# psoc6a2m register map
Vendor: Cypress Semiconductor; Series: psoc6a2m; File version: 1.0
CPU: CM4 r0p1, little endian, MPU, FPU, VTOR, 3 interrupt priority bits
Registers are 32-bit, read-write, reset 0x0 unless marked. A register's access mark holds for its fields unless they carry their own. Offsets are from the block's base; [hi:lo] are bit positions; lines under a group give offsets from that group.

## SDHC0 (part 3 of 4) — SD/eMMC Host Controller
Base 0x40460000
Same registers: SDHC1 0x40470000
0x1000 CORE group — MMIO for Synopsys Mobile Storage Host Controller IP
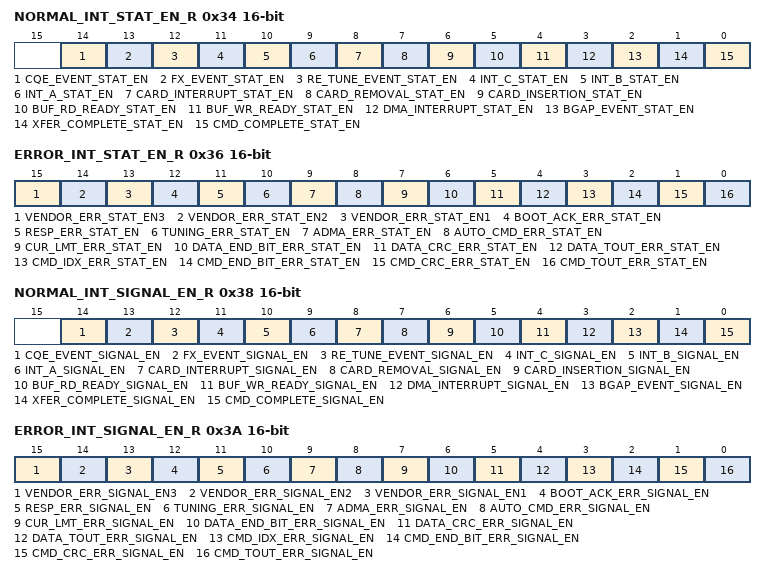
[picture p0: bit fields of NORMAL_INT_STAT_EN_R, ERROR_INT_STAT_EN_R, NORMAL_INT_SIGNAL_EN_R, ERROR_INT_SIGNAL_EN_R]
  0x34 NORMAL_INT_STAT_EN_R 16-bit — Normal Interrupt Status Enable Register
    [14] CQE_EVENT_STAT_EN — CQE Event Status Enable Values: - 0x0 (FALSE): Masked - 0x1 (TRUE): Enabled
    [13] FX_EVENT_STAT_EN — FX Event Status Enable This bit is added from Version 4.10. Values: - 0x0 (FALSE): Masked - 0x1 (TRUE): Enabled
    [12] RE_TUNE_EVENT_STAT_EN — Re-Tuning Event (UHS-I only) Status Enable Values: - 0x0 (FALSE): Masked - 0x1 (TRUE): Enabled
    [11] INT_C_STAT_EN — INT_C (Embedded) Status Enable If this bit is set to 0, the Host Controller clears the interrupt request to the System. The Host Driver may clear this bit before servicing the INT_C and may set this bit again after all interrupt requests to INT_C pin are cleared to prevent inadvertent interrupts. Values: - 0x0 (FALSE): Masked - 0x1 (TRUE): Enabled
    [10] INT_B_STAT_EN — INT_B (Embedded) Status Enable If this bit is set to 0, the Host Controller clears the interrupt request to the System. The Host Driver may clear this bit before servicing the INT_B and may set this bit again after all interrupt requests to INT_B pin are cleared to prevent inadvertent interrupts. Values: - 0x0 (FALSE): Masked - 0x1 (TRUE): Enabled
    [9] INT_A_STAT_EN — INT_A (Embedded) Status Enable If this bit is set to 0, the Host Controller clears the interrupt request to the System. The Host Driver may clear this bit before servicing the INT_A and may set this bit again after all interrupt requests to INT_A pin are cleared to prevent inadvertent interrupts. Values: - 0x0 (FALSE): Masked - 0x1 (TRUE): Enabled
    [8] CARD_INTERRUPT_STAT_EN — Card Interrupt Status Enable If this bit is set to 0, the Host Controller clears the interrupt request to the System. The Card Interrupt detection is stopped when this bit is cleared and restarted when this bit is set to 1. The Host Driver may clear the Card Interrupt Status Enable before servicing the Card Interrupt and may set this bit again after all interrupt requests from the card are cleared to prevent inadvertent interrupts. By setting this bit to 0, interrupt input must be masked by implementation so that the interrupt input is not affected by external signal in any state (for example, floating). Values: - 0x0 (FALSE): Masked - 0x1 (TRUE): Enabled
    [7] CARD_REMOVAL_STAT_EN — Card Removal Status Enable Values: - 0x0 (FALSE): Masked - 0x1 (TRUE): Enabled
    [6] CARD_INSERTION_STAT_EN — Card Insertion Status Enable Values: - 0x0 (FALSE): Masked - 0x1 (TRUE): Enabled
    [5] BUF_RD_READY_STAT_EN — Buffer Read Ready Status Enable Values: - 0x0 (FALSE): Masked - 0x1 (TRUE): Enabled
    [4] BUF_WR_READY_STAT_EN — Buffer Write Ready Status Enable Values: - 0x0 (FALSE): Masked - 0x1 (TRUE): Enabled
    [3] DMA_INTERRUPT_STAT_EN — DMA Interrupt Status Enable Values: - 0x0 (FALSE): Masked - 0x1 (TRUE): Enabled
    [2] BGAP_EVENT_STAT_EN — Block Gap Event Status Enable Values: - 0x0 (FALSE): Masked - 0x1 (TRUE): Enabled
    [1] XFER_COMPLETE_STAT_EN — Transfer Complete Status Enable Values: - 0x0 (FALSE): Masked - 0x1 (TRUE): Enabled
    [0] CMD_COMPLETE_STAT_EN — Command Complete Status Enable Values: - 0x0 (FALSE): Masked - 0x1 (TRUE): Enabled
  0x36 ERROR_INT_STAT_EN_R 16-bit — Error Interrupt Status Enable Register
    [15] VENDOR_ERR_STAT_EN3
    [14] VENDOR_ERR_STAT_EN2
    [13] VENDOR_ERR_STAT_EN1
    [12] BOOT_ACK_ERR_STAT_EN — Boot Acknowledgment Error (eMMC Mode only) Setting this bit to 1 enables setting of Boot Acknowledgment Error in Error Interrupt Status register (ERROR_INT_STAT_R). Values: - 0x0 (FALSE): Masked - 0x1 (TRUE): Enabled
    [11] RESP_ERR_STAT_EN — Response Error Status Enable (SD Mode only) Values: - 0x0 (FALSE): Masked - 0x1 (TRUE): Enabled
    [10] TUNING_ERR_STAT_EN — Tuning Error Status Enable (UHS-I Mode only) Values: - 0x0 (FALSE): Masked - 0x1 (TRUE): Enabled
    [9] ADMA_ERR_STAT_EN — ADMA Error Status Enable Values: - 0x0 (FALSE): Masked - 0x1 (TRUE): Enabled
    [8] AUTO_CMD_ERR_STAT_EN — Auto CMD Error Status Enable (SD/eMMC Mode only). Values: - 0x0 (FALSE): Masked - 0x1 (TRUE): Enabled
    [7] CUR_LMT_ERR_STAT_EN — Current Limit Error Status Enable Values: - 0x0 (FALSE): Masked - 0x1 (TRUE): Enabled
    [6] DATA_END_BIT_ERR_STAT_EN — Data End Bit Error Status Enable (SD/eMMC Mode only). Values: - 0x0 (FALSE): Masked - 0x1 (TRUE): Enabled
    [5] DATA_CRC_ERR_STAT_EN — Data CRC Error Status Enable (SD/eMMC Mode only) Values: - 0x0 (FALSE): Masked - 0x1 (TRUE): Enabled
    [4] DATA_TOUT_ERR_STAT_EN — Data Timeout Error Status Enable (SD/eMMC Mode only) Values: - 0x0 (FALSE): Masked - 0x1 (TRUE): Enabled
    [3] CMD_IDX_ERR_STAT_EN — Command Index Error Status Enable (SD/eMMC Mode only) Values: - 0x0 (FALSE): Masked - 0x1 (TRUE): Enabled
    [2] CMD_END_BIT_ERR_STAT_EN — Command End Bit Error Status Enable (SD/eMMC Mode only) Values: - 0x0 (FALSE): Masked - 0x1 (TRUE): Enabled
    [1] CMD_CRC_ERR_STAT_EN — ommand CRC Error Status Enable (SD/eMMC Mode only) Values: - 0x0 (FALSE): Masked - 0x1 (TRUE): Enabled
    [0] CMD_TOUT_ERR_STAT_EN — Command Timeout Error Status Enable (SD/eMMC Mode only). Values: - 0x0 (FALSE): Masked - 0x1 (TRUE): Enabled
  0x38 NORMAL_INT_SIGNAL_EN_R 16-bit — Normal Interrupt Signal Enable Register
    [14] CQE_EVENT_SIGNAL_EN — Command Queuing Engine Event Signal Enable Values: - 0x0 (FALSE): Masked - 0x1 (TRUE): Enabled
    [13] FX_EVENT_SIGNAL_EN — FX Event Signal Enable Values: - 0x0 (FALSE): Masked - 0x1 (TRUE): Enabled
    [12] RE_TUNE_EVENT_SIGNAL_EN — Re-Tuning Event (UHS-I only) Signal Enable. Values: - 0x0 (FALSE): Masked - 0x1 (TRUE): Enabled
    [11] INT_C_SIGNAL_EN — INT_C (Embedded) Signal Enable Values: - 0x0 (FALSE): Masked - 0x1 (TRUE): Enabled
    [10] INT_B_SIGNAL_EN — INT_B (Embedded) Signal Enable Values: - 0x0 (FALSE): Masked - 0x1 (TRUE): Enabled
    [9] INT_A_SIGNAL_EN — INT_A (Embedded) Signal Enable Values: - 0x0 (FALSE): Masked - 0x1 (TRUE): Enabled
    [8] CARD_INTERRUPT_SIGNAL_EN — Card Interrupt Signal Enable Values: - 0x0 (FALSE): Masked - 0x1 (TRUE): Enabled
    [7] CARD_REMOVAL_SIGNAL_EN — Card Removal Signal Enable Values: - 0x0 (FALSE): Masked - 0x1 (TRUE): Enabled
    [6] CARD_INSERTION_SIGNAL_EN — Card Insertion Signal Enable Values: - 0x0 (FALSE): Masked - 0x1 (TRUE): Enabled
    [5] BUF_RD_READY_SIGNAL_EN — Buffer Read Ready Signal Enable Values: - 0x0 (FALSE): Masked - 0x1 (TRUE): Enabled
    [4] BUF_WR_READY_SIGNAL_EN — Buffer Write Ready Signal Enable Values: - 0x0 (FALSE): Masked - 0x1 (TRUE): Enabled
    [3] DMA_INTERRUPT_SIGNAL_EN — DMA Interrupt Signal Enable Values: - 0x0 (FALSE): Masked - 0x1 (TRUE): Enabled
    [2] BGAP_EVENT_SIGNAL_EN — Block Gap Event Signal Enable Values: - 0x0 (FALSE): Masked - 0x1 (TRUE): Enabled
    [1] XFER_COMPLETE_SIGNAL_EN — Transfer Complete Signal Enable Values: - 0x0 (FALSE): Masked - 0x1 (TRUE): Enabled
    [0] CMD_COMPLETE_SIGNAL_EN — Command Complete Signal Enable Values: - 0x0 (FALSE): Masked - 0x1 (TRUE): Enabled
  0x3A ERROR_INT_SIGNAL_EN_R 16-bit — Error Interrupt Signal Enable Register
    [15] VENDOR_ERR_SIGNAL_EN3
    [14] VENDOR_ERR_SIGNAL_EN2
    [13] VENDOR_ERR_SIGNAL_EN1
    [12] BOOT_ACK_ERR_SIGNAL_EN — Boot Acknowledgment Error (eMMC Mode only). Setting this bit to 1 enables generating interrupt signal when Boot Acknowledgement Error in Error Interrupt Status register is set. Values: - 0x0 (FALSE): Masked - 0x1 (TRUE): Enabled
    [11] RESP_ERR_SIGNAL_EN — Response Error Signal Enable (SD Mode only) Values: - 0x0 (FALSE): Masked - 0x1 (TRUE): Enabled
    [10] TUNING_ERR_SIGNAL_EN — Tuning Error Signal Enable (UHS-I Mode only) Values: - 0x0 (FALSE): Masked - 0x1 (TRUE): Enabled
    [9] ADMA_ERR_SIGNAL_EN — ADMA Error Signal Enable Values: - 0x0 (FALSE): Masked - 0x1 (TRUE): Enabled
    [8] AUTO_CMD_ERR_SIGNAL_EN — Auto CMD Error Signal Enable (SD/eMMC Mode only) Values: - 0x0 (FALSE): Masked - 0x1 (TRUE): Enabled
    [7] CUR_LMT_ERR_SIGNAL_EN — Current Limit Error Signal Enable Values: - 0x0 (FALSE): Masked - 0x1 (TRUE): Enabled
    [6] DATA_END_BIT_ERR_SIGNAL_EN — Data End Bit Error Signal Enable (SD/eMMC Mode only) Values: - 0x0 (FALSE): Masked - 0x1 (TRUE): Enabled
    [5] DATA_CRC_ERR_SIGNAL_EN — Data CRC Error Signal Enable (SD/eMMC Mode only) Values: - 0x0 (FALSE): Masked - 0x1 (TRUE): Enabled
    [4] DATA_TOUT_ERR_SIGNAL_EN — Data Timeout Error Signal Enable (SD/eMMC Mode only) Values: - 0x0 (FALSE): Masked - 0x1 (TRUE): Enabled
    [3] CMD_IDX_ERR_SIGNAL_EN — Command Index Error Signal Enable (SD/eMMC Mode only) Values: - 0x0 (FALSE): No error - 0x1 (TRUE): Error
    [2] CMD_END_BIT_ERR_SIGNAL_EN — Command End Bit Error Signal Enable (SD/eMMC Mode only) Values: - 0x0 (FALSE): Masked - 0x1 (TRUE): Enabled
    [1] CMD_CRC_ERR_SIGNAL_EN — Command CRC Error Signal Enable (SD/eMMC Mode only) Values: - 0x0 (FALSE): Masked - 0x1 (TRUE): Enabled
    [0] CMD_TOUT_ERR_SIGNAL_EN — Command Timeout Error Signal Enable (SD/eMMC Mode only) Values: - 0x0 (FALSE): Masked - 0x1 (TRUE): Enabled
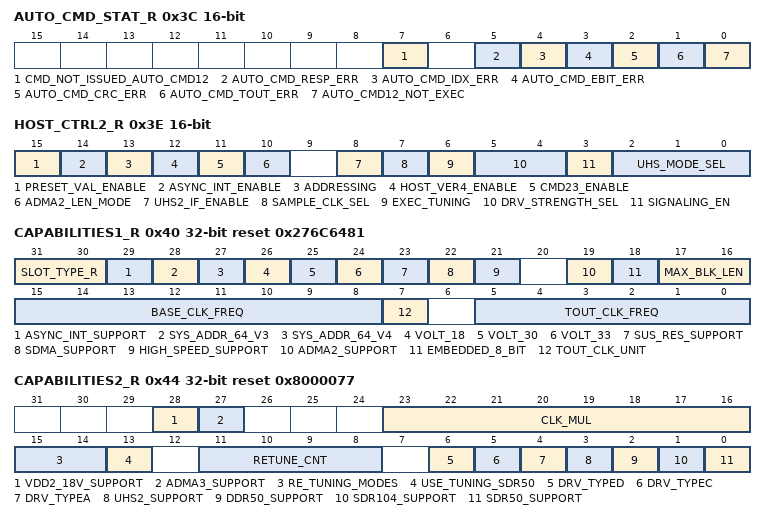
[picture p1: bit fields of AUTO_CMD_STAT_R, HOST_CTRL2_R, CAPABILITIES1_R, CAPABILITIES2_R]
  0x3C AUTO_CMD_STAT_R 16-bit ro — Auto CMD Status Register
    [7] CMD_NOT_ISSUED_AUTO_CMD12 — Command Not Issued By Auto CMD12 Error If this bit is set to 1, CMD_wo_DAT is not executed due to an Auto CMD12 Error (D04-D01) in this register. This bit is set to 0 when Auto CMD Error is generated by Auto CMD23. Values: - 0x1 (TRUE): Not Issued - 0x0 (FALSE): No Error
    [5] AUTO_CMD_RESP_ERR — Auto CMD Response Error This bit is set when Response Error Check Enable in the Transfer Mode register is set to 1 and an error is detected in R1 response of either Auto CMD12 or CMD13. This status is ignored if any bit between D00 to D04 is set to 1. Values: - 0x1 (TRUE): Error - 0x0 (FALSE): No Error
    [4] AUTO_CMD_IDX_ERR — Auto CMD Index Error This bit is set if the command index error occurs in response to a command. Values: - 0x1 (TRUE): Error - 0x0 (FALSE): No Error
    [3] AUTO_CMD_EBIT_ERR — Auto CMD End Bit Error This bit is set when detecting that the end bit of command response is 0. Values: - 0x1 (TRUE): End Bit Error Generated - 0x0 (FALSE): No Error
    [2] AUTO_CMD_CRC_ERR — Auto CMD CRC Error This bit is set when detecting a CRC error in the command response. Values: - 0x1 (TRUE): CRC Error Generated - 0x0 (FALSE): No Error
    [1] AUTO_CMD_TOUT_ERR — Auto CMD Timeout Error This bit is set if no response is returned with 64 SDCLK cycles from the end bit of the command. If this bit is set to 1, error status bits (D04-D01) are meaningless. Values: - 0x1 (TRUE): Time out - 0x0 (FALSE): No Error
    [0] AUTO_CMD12_NOT_EXEC — Auto CMD12 Not Executed If multiple memory block data transfer is not started due to a command error, this bit is not set because it is not necessary to issue an Auto CMD12. Setting this bit to 1 means that the Host Controller cannot issue Auto CMD12 to stop multiple memory block data transfer, due to some error. If this bit is set to 1, error status bits (D04-D01) is meaningless. This bit is set to 0 when Auto CMD Error is generated by Auto CMD23. Values: - 0x1 (TRUE): Not Executed - 0x0 (FALSE): Executed
  0x3E HOST_CTRL2_R 16-bit — Host Control 2 Register
    [15] PRESET_VAL_ENABLE — Preset Value Enable This bit enables automatic selection of SDCLK frequency and Driver strength Preset Value registers. When Preset Value Enable is set, SDCLK frequency generation (Frequency Select and Clock Generator Select) and the driver strength selection are performed by the controller. These values are selected from set of Preset Value registers based on selected speed mode. Note: For more information, see the FAQ on Preset Register in the DWC_mshc Databook. Values: - 0x0 (FALSE): SDCLK and Driver Strength are controlled by Host Driver - 0x1 (TRUE): Automatic Selection by Preset Value are Enabled
    [14] ASYNC_INT_ENABLE — Asynchronous Interrupt Enable This bit can be set if a card supports asynchronous interrupts and Asynchronous Interrupt Support is set to 1 in the Capabilities register. Values: - 0x0 (FALSE): Disabled - 0x1 (TRUE): Enabled
    [13] ADDRESSING — 64-bit Addressing This bit is effective when Host Version 4 Enable is set to 1. Values: - 0x0 (FALSE): 32 bits addressing - 0x1 (TRUE): 64 bits addressing
    [12] HOST_VER4_ENABLE — Host Version 4 Enable This bit selects either Version 3.00 compatible mode or Version 4 mode. Functions of following fields are modified for Host Version 4 mode: - SDMA Address: SDMA uses ADMA System Address (05Fh-058h) instead of SDMA System Address register (003h-000h) - ADMA2/ADMA3 selection: ADMA3 is selected by DMA select in Host Control 1 register - 64-bit ADMA Descriptor Size: 128-bit descriptor is used instead of 96-bit descriptor when 64-bit Addressing is set to 1 - Selection of 32-bit/64-bit System Addressing: Either 32- bit or 64-bit system addressing is selected by 64-bit Addressing bit in this register - 32-bit Block Count: SDMA System Address register (003h-000h) is modified to 32-bit Block Count register Note: It is recommended not to program ADMA3 Integrated Descriptor Address registers, UHS-II registers and Command Queuing registers (if applicable) while operating in Host version less than 4 mode (Host Version 4 Enable = 0). Values: - 0x0 (FALSE): Version 3.00 compatible mode - 0x1 (TRUE): Version 4 mode
    [11] CMD23_ENABLE — CMD23 Enable If the card supports CMD23, this bit is set to 1. This bit is used to select Auto CMD23 or Auto CMD12 for ADMA3 data transfer. Values: - 0x0 (FALSE): Auto CMD23 is disabled - 0x1 (TRUE): Auto CMD23 is enabled
    [10] ADMA2_LEN_MODE — ADMA2 Length Mode This bit selects ADMA2 Length mode to be either 16-bit or 26-bit. Values: - 0x0 (FALSE): 16-bit Data Length Mode - 0x1 (TRUE): 26-bit Data Length Mode
    [8] UHS2_IF_ENABLE — UHS-II Interface Enable This bit is used to enable the UHS-II Interface. The value is reflected on the uhs2_if_en pin. Values: - 0x0 (FALSE): SD/eMMC Interface Enabled - 0x1 (TRUE): UHS-II Interface Enabled
    [7] SAMPLE_CLK_SEL — Sampling Clock Select This bit is used by the Host Controller to select the sampling clock in SD/eMMC mode to receive CMD and DAT. This bit is set by the tuning procedure and is valid after the completion of tuning (when Execute Tuning is cleared). Setting this bit to 1 means that tuning is completed successfully and setting this bit to 0 means that tuning has failed. The value is reflected on the sample_cclk_sel pin.This bit is irrelevant in UHS-II mode Values: - 0x0 (FALSE): Fixed clock is used to sample data - 0x1 (TRUE): Tuned clock is used to sample data
    [6] EXEC_TUNING — Execute Tuning This bit is set to 1 to start the tuning procedure in UHSI/ eMMC speed modes and this bit is automatically cleared when tuning procedure is completed.This bit is irrelevant in UHS-II mode Values: - 0x0 (FALSE): Not Tuned or Tuning completed - 0x1 (TRUE): Execute Tuning
    [5:4] DRV_STRENGTH_SEL — Driver Strength Select These bits are used to select the Host Controller output driver in 1.8V signaling UHS-I/eMMC speed modes. They depend on setting of Preset Value Enable. The value is reflected on the io_drive_strength[1:0] output. - 0x0 (TYPEB): Driver TYPEB is selected - 0x1 (TYPEA): Driver TYPEA is selected - 0x2 (TYPEC): Driver TYPEC is selected - 0x3 (TYPED): Driver TYPED is selected
    [3] SIGNALING_EN — 1.8V Signaling Enable This bit controls voltage regulator for I/O cell in SD UHS-I mode. Setting this bit from 0 to 1 starts changing the signal voltage from 3.3V to 1.8V. Host Controller clears this bit if switching to 1.8V signaling fails per protocol. The value is reflected on the io_volt_sel output which can then be used to change an external regulator to supply 1.8V instead of 3.3V on the VDDIO pin associated with the CLK/CMD/DAT signals. Note: This bit must be set for all UHS-I speed modes (SDR12/SDR25/SDR50/SDR104/DDR50). Values: - 0x0 (V_3_3): 3.3V Signalling - 0x1 (V_1_8): 1.8V Signalling
    [2:0] UHS_MODE_SEL
  0x40 CAPABILITIES1_R ro reset 0x276C6481 — Capabilities 1 Register - 0 to 31
    [31:30] SLOT_TYPE_R — Slot Type These bits indicate usage of a slot by a specific Host System. Values: - 0x0 (REMOVABLE_SLOT): Removable Card Slot - 0x1 (EMBEDDED_SLOT): Embedded Slot for one Device - 0x2 (SHARED_SLOT): Shared Bus Slot (SD mode) - 0x3 (UHS2_EMBEDDED_SLOT): UHS-II Multiple Embedded Devices
    [29] ASYNC_INT_SUPPORT — Asynchronous Interrupt Support (SD Mode only) Values: - 0x0 (FALSE): Asynchronous Interrupt Not Supported - 0x1 (TRUE): Asynchronous Interrupt Supported
    [28] SYS_ADDR_64_V3 — 64-bit System Address Support for V3 This bit sets the Host controller to support 64-bit System Addressing of V3 mode. SDMA cannot be used in 64-bit Addressing in Version 3 Mode. If this bit is set to 1, 64-bit ADMA2 with using 96-bit Descriptor can be enabled by setting Host Version 4 Enable (HOST_VER4_ENABLE = 0) and DMA select (DMA_SEL = 11b). Values: - 0x0 (FALSE): 64-bit System Address for V3 is Not Supported - 0x1 (TRUE): 64-bit System Address for V3 is Supported
    [27] SYS_ADDR_64_V4 — 64-bit System Address Support for V4 This bit sets the Host Controller to support 64-bit System Addressing of V4 mode. When this bit is set to 1, full or part of 64-bit address must be used to decode the Host Controller Registers so that Host Controller Registers can be placed above system memory area. 64-bit address decode of Host Controller registers is effective regardless of setting to 64-bit Addressing in Host Control 2. If this bit is set to 1, 64-bit DMA Addressing for version 4 is enabled by setting Host Version 4 Enable (HOST_VER4_ENABLE = 1) and by setting 64-bit Addressing (ADDRESSING =1) in the Host Control 2 register. SDMA can be used and ADMA2 uses 128-bit Descriptor. Values: - 0x0 (FALSE): 64-bit System Address for V4 is Not Supported - 0x1 (TRUE): 64-bit System Address for V4 is Supported
    [26] VOLT_18 — Voltage Support 1.8V Values: - 0x0 (FALSE): 1.8V Not Supported - 0x1 (TRUE): 1.8V Supported
    [25] VOLT_30 — Voltage Support 3.0V Values: - 0x0 (FALSE): 3.0V Not Supported - 0x1 (TRUE): 3.0V Supported
    [24] VOLT_33 — Voltage Support 3.3V Values: - 0x0 (FALSE): 3.3V Not Supported - 0x1 (TRUE): 3.3V Supported
    [23] SUS_RES_SUPPORT — Suspense/Resume Support This bit indicates whether the Host Controller supports Suspend/Resume functionality. If this bit is 0, the Host Driver does not issue either Suspend or Resume commands because the Suspend and Resume mechanism is not supported. Values: - 0x0 (FALSE): Not Supported - 0x1 (TRUE): Supported
    [22] SDMA_SUPPORT — SDMA Support This bit indicates whether the Host Controller is capable of using SDMA to transfer data between the system memory and the Host Controller directly. Values: - 0x0 (FALSE): SDMA not Supported - 0x1 (TRUE): SDMA Supported
    [21] HIGH_SPEED_SUPPORT — High Speed Support This bit indicates whether the Host Controller and the Host System supports High Speed mode and they can supply the SD Clock frequency from 25 MHz to 50 MHz. Values: - 0x0 (FALSE): High Speed not Supported - 0x1 (TRUE): High Speed Supported
    [19] ADMA2_SUPPORT — ADMA2 Support This bit indicates whether the Host Controller is capable of using ADMA2. Values: - 0x0 (FALSE): ADMA2 not Supported - 0x1 (TRUE): ADMA2 Supported
    [18] EMBEDDED_8_BIT — 8-bit Support for Embedded Device This bit indicates whether the Host Controller is capable of using an 8-bit bus width mode. This bit is not effective when the Slot Type is set to 10b. Values: - 0x0 (FALSE): 8-bit Bus Width not Supported - 0x1 (TRUE): 8-bit Bus Width Supported
    [17:16] MAX_BLK_LEN
    [15:8] BASE_CLK_FREQ — Base Clock Frequency for SD clock These bits indicate the base (maximum) clock frequency for the SD Clock. The definition of these bits depend on the Host Controller Version. - 6-Bit Base Clock Frequency: This mode is supported by the Host Controller version 1.00 and 2.00. The upper 2 bits are not effective and are always 0. The unit values are 1 MHz. The supported clock range is 10 MHz to 63 MHz. - 0x00 - Get information through another method - 0x01 - 1 MHz - 0x02 - 2 MHz - ............. - 0x3F - 63 MHz - 0x40-0xFF - Not Supported - 8-Bit Base Clock Frequency: This mode is supported by the Host Controller version 3.00. The unit values are 1 MHz. The supported clock range is 10 MHz to 255 MHz. - 0x00 - Get information through another method - 0x01 - 1 MHz - 0x02 - 2 MHz - ............ - 0xFF - 255 MHz If the frequency is 16.5 MHz, the larger value is set to 0001001b (17 MHz) because the Host Driver uses this value to calculate the clock divider value and it does not exceed the upper limit of the SD Clock frequency. If these bits are all 0, the Host system has to get information using a different method.
    [7] TOUT_CLK_UNIT — Timeout Clock Unit This bit shows the unit of base clock frequency used to detect Data TImeout Error. Values: - 0x0 (KHZ): KHz - 0x1 (MHZ): MHz
    [5:0] TOUT_CLK_FREQ — Timeout Clock Frequency This bit shows the base clock frequency used to detect Data Timeout Error. The Timeout Clock unit defines the unit of timeout clock frequency. It can be KHz or MHz. - 0x00 - Get information through another method - 0x01 - 1KHz / 1MHz - 0x02 - 2KHz / 2MHz - 0x03 - 3KHz / 3MHz - ........... - 0x3F - 63KHz / 63MHz
  0x44 CAPABILITIES2_R ro reset 0x8000077 — Capabilities Register - 32 to 63
    [28] VDD2_18V_SUPPORT — 1.8V VDD2 Support This bit indicates support of VDD2 for the Host System. Values: - 0x0 (FALSE): 1.8V VDD2 is not Supported - 0x1 (TRUE): 1.8V VDD2 is Supported
    [27] ADMA3_SUPPORT — ADMA3 Support This bit indicates whether the Host Controller is capable of using ADMA3. Values: - 0x0 (FALSE): ADMA3 not Supported - 0x1 (TRUE): ADMA3 Supported
    [23:16] CLK_MUL — Clock Multiplier These bits indicate the clock multiplier of the programmable clock generator. Setting these bits to 0 means that the Host Controller does not support a programmable clock generator. - 0x0: Clock Multiplier is not Supported - 0x1: Clock Multiplier M = 2 - 0x2: Clock Multiplier M = 3 - ......... - 0xFF: Clock Multiplier M = 256
    [15:14] RE_TUNING_MODES
    [13] USE_TUNING_SDR50 — Use Tuning for SDR50 (UHS-I only) Values: - 0x0 (ZERO): SDR50 does not require tuning - 0x1 (ONE): SDR50 requires tuning
    [11:8] RETUNE_CNT
    [6] DRV_TYPED — Driver Type D Support (UHS-I only) This bit indicates support of Driver Type D for 1.8 Signaling. Values: - 0x0 (FALSE): Driver Type D is not supported - 0x1 (TRUE): Driver Type D is supported
    [5] DRV_TYPEC — Driver Type C Support (UHS-I only) This bit indicates support of Driver Type C for 1.8 Signaling. Values: - 0x0 (FALSE): Driver Type C is not supported - 0x1 (TRUE): Driver Type C is supported
    [4] DRV_TYPEA — Driver Type A Support (UHS-I only) This bit indicates support of Driver Type A for 1.8 Signaling. Values: - 0x0 (FALSE): Driver Type A is not supported - 0x1 (TRUE): Driver Type A is supported
    [3] UHS2_SUPPORT — UHS-II Support (UHS-II only) This bit indicates whether Host Controller supports UHS-II. Values: - 0x0 (FALSE): UHS-II is not supported - 0x1 (TRUE): UHS-II is supported
    [2] DDR50_SUPPORT — DDR50 Support (UHS-I only) Values: - 0x0 (FALSE): DDR50 is not supported - 0x1 (TRUE): DDR50 is supported
    [1] SDR104_SUPPORT — SDR104 Support (UHS-I only) This bit mentions that SDR104 requires tuning. Values: - 0x0 (FALSE): SDR104 is not supported - 0x1 (TRUE): SDR104 is supported
    [0] SDR50_SUPPORT — SDR50 Support (UHS-I only) Thsi bit indicates that SDR50 is supported. The bit 13 (USE_TUNING_SDR50) indicates whether SDR50 requires tuning or not. Values: - 0x0 (FALSE): SDR50 is not supported - 0x1 (TRUE): SDR50 is supported
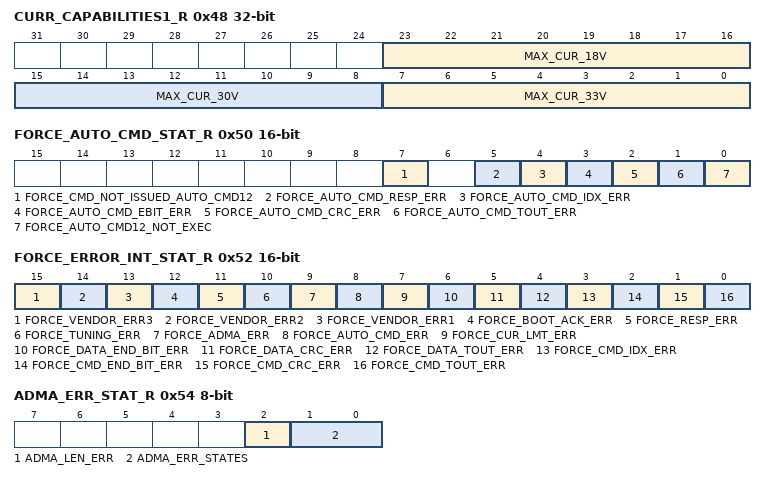
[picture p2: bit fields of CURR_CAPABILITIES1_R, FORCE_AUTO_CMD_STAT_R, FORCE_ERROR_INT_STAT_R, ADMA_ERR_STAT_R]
  0x48 CURR_CAPABILITIES1_R ro — Current Capabilities Register - 0 to 31
    [23:16] MAX_CUR_18V — Maximum Current for 1.8V This bit specifies the Maximum Current for 1.8V VDD1 power supply for the card. - 0: Get information through another method - 1: 4mA - 2: 8mA - 3: 13mA - ....... - 255: 1020mA
    [15:8] MAX_CUR_30V — Maximum Current for 3.0V This bit specifies the Maximum Current for 3.0V VDD1 power supply for the card. - 0: Get information through another method - 1: 4mA - 2: 8mA - 3: 13mA - ....... - 255: 1020mA
    [7:0] MAX_CUR_33V — Maximum Current for 3.3V This bit specifies the Maximum Current for 3.3V VDD1 power supply for the card. - 0: Get information through another method - 1: 4mA - 2: 8mA - 3: 13mA - ....... - 255: 1020mA
  0x4C CURR_CAPABILITIES2_R ro — Maximum Current Capabilities Register - 32 to 63
    [7:0] MAX_CUR_VDD2_18V — Maximum Current for 1.8V VDD2 This bit specifies the Maximum Current for 1.8V VDD2 power supply for the UHS-II card. - 0: Get information through another method - 1: 4mA - 2: 8mA - 3: 13mA - ....... - 255: 1020mA
  0x50 FORCE_AUTO_CMD_STAT_R 16-bit wo — Force Event Register for Auto CMD Error Status register
    [7] FORCE_CMD_NOT_ISSUED_AUTO_CMD12 — Force Event for Command Not Issued By Auto CMD12 Error Values: - 0x1 (TRUE): Command Not Issued By Auto CMD12 Error Status is set - 0x0 (FALSE): Not Affected
    [5] FORCE_AUTO_CMD_RESP_ERR — Force Event for Auto CMD Response Error Values: - 0x1 (TRUE): Auto CMD Response Error Status is set - 0x0 (FALSE): Not Affected
    [4] FORCE_AUTO_CMD_IDX_ERR — Force Event for Auto CMD Index Error Values: - 0x1 (TRUE): Auto CMD Index Error Status is set - 0x0 (FALSE): Not Affected
    [3] FORCE_AUTO_CMD_EBIT_ERR — Force Event for Auto CMD End Bit Error Values: - 0x1 (TRUE): Auto CMD End Bit Error Status is set - 0x0 (FALSE): Not Affected
    [2] FORCE_AUTO_CMD_CRC_ERR — Force Event for Auto CMD CRC Error Values: - 0x1 (TRUE): Auto CMD CRC Error Status is set - 0x0 (FALSE): Not Affected
    [1] FORCE_AUTO_CMD_TOUT_ERR — Force Event for Auto CMD Timeout Error Values: - 0x1 (TRUE): Auto CMD Timeout Error Status is set - 0x0 (FALSE): Not Affected
    [0] FORCE_AUTO_CMD12_NOT_EXEC — Force Event for Auto CMD12 Not Executed Values: - 0x1 (TRUE): Auto CMD12 Not Executed Status is set - 0x0 (FALSE): Not Affected
  0x52 FORCE_ERROR_INT_STAT_R 16-bit — Force Event Register for Error Interrupt Status
    [15] FORCE_VENDOR_ERR3
    [14] FORCE_VENDOR_ERR2
    [13] FORCE_VENDOR_ERR1
    [12] FORCE_BOOT_ACK_ERR — Force Event for Boot Ack error Values: - 0x0 (FALSE): Not Affected - 0x1 (TRUE): Boot ack Error Status is set
    [11] FORCE_RESP_ERR — Force Event for Response Error (SD Mode only) Values: - 0x0 (FALSE): Not Affected - 0x1 (TRUE): Response Error Status is set
    [10] FORCE_TUNING_ERR — Force Event for Tuning Error (UHS-I Mode only) Values: - 0x0 (FALSE): Not Affected - 0x1 (TRUE): Tuning Error Status is set
    [9] FORCE_ADMA_ERR — Force Event for ADMA Error Values: - 0x0 (FALSE): Not Affected - 0x1 (TRUE): ADMA Error Status is set
    [8] FORCE_AUTO_CMD_ERR — Force Event for Auto CMD Error (SD/eMMC Mode only) Values: - 0x0 (FALSE): Not Affected - 0x1 (TRUE): Auto CMD Error Status is set
    [7] FORCE_CUR_LMT_ERR — Force Event for Current Limit Error Values: - 0x0 (FALSE): Not Affected - 0x1 (TRUE): Current Limit Error Status is set
    [6] FORCE_DATA_END_BIT_ERR — Force Event for Data End Bit Error (SD/eMMC Mode only) Values: - 0x0 (FALSE): Not Affected - 0x1 (TRUE): Data End Bit Error Status is set
    [5] FORCE_DATA_CRC_ERR — Force Event for Data CRC Error (SD/eMMC Mode only) Values: - 0x0 (FALSE): Not Affected - 0x1 (TRUE): Data CRC Error Status is set
    [4] FORCE_DATA_TOUT_ERR — Force Event for Data Timeout Error (SD/eMMC Mode only) Values: - 0x0 (FALSE): Not Affected - 0x1 (TRUE): Data Timeout Error Status is set
    [3] FORCE_CMD_IDX_ERR — Force Event for Command Index Error (SD/eMMC Mode only) Values: - 0x0 (FALSE): Not Affected - 0x1 (TRUE): Command Index Error Status is set
    [2] FORCE_CMD_END_BIT_ERR — Force Event for Command End Bit Error (SD/eMMC Mode only) Values: - 0x0 (FALSE): Not Affected - 0x1 (TRUE): Command End Bit Error Status is set
    [1] FORCE_CMD_CRC_ERR — Force Event for Command CRC Error (SD/eMMC Mode only) Values: - 0x0 (FALSE): Not Affected - 0x1 (TRUE): Command CRC Error Status is set
    [0] FORCE_CMD_TOUT_ERR — Force Event for Command Timeout Error (SD/eMMC Mode only) Values: - 0x0 (FALSE): Not Affected - 0x1 (TRUE): Command Timeout Error Status is set
  0x54 ADMA_ERR_STAT_R 8-bit ro — ADMA Error Status Register
    [2] ADMA_LEN_ERR — ADMA Length Mismatch Error States This error occurs in the following instances: - While the Block Count Enable is being set, the total data length specified by the Descriptor table is different from that specified by the Block Count and Block Length - When the total data length cannot be divided by the block length Values: - 0x0 (NO_ERR): No Error - 0x1 (ERROR): Error
    [1:0] ADMA_ERR_STATES — ADMA Error States These bits indicate the state of ADMA when an error occurs during ADMA data transfer. Values: - 0x0 (ST_STOP): Stop DMA - SYS_ADR register points to a location next to the error descriptor - 0x1 (ST_FDS): Fetch Descriptor - SYS_ADR register points to the error descriptor - 0x2 (UNUSED): Never set this state - 0x3 (ST_TFR): Transfer Data - SYS_ADR register points to a location next to the error descriptor
  0x58 ADMA_SA_LOW_R — ADMA System Address Register - Low
    [31:0] ADMA_SA_LOW — ADMA System Address These bits indicate the lower 32 bits of the ADMA system address. - SDMA: If Host Version 4 Enable is set to 1, this register stores the system address of the data location - ADMA2: This register stores the byte address of the executing command of the descriptor table - ADMA3: This register is set by ADMA3. ADMA2 increments the address of this register that points to the next line, every time a Descriptor line is fetched.
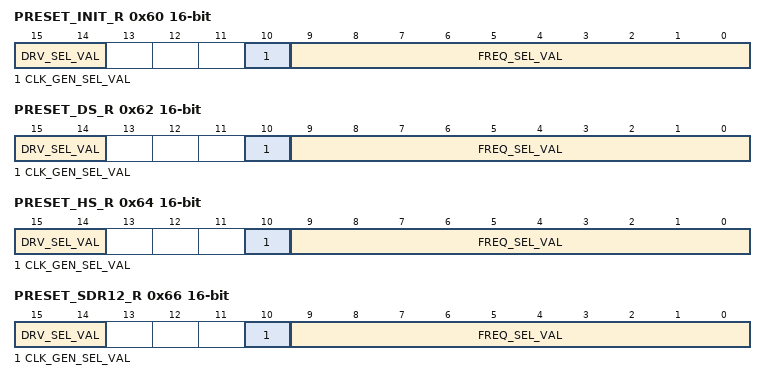
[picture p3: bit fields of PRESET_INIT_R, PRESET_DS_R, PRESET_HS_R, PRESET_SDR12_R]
  0x60 PRESET_INIT_R 16-bit ro — Preset Value for Initialization
    [15:14] DRV_SEL_VAL — Driver Strength Select Value These bits indicate that the Driver strength is supported by 1.8V signaling bus speed modes. These bits are meaningless for 3.3V signaling. Values: - 0x0 (TYPEB): Driver Type B is selected - 0x1 (TYPEA): Driver Type A is selected - 0x2 (TYPEC): Driver Type C is selected - 0x3 (TYPED): Driver Type D is selected
    [10] CLK_GEN_SEL_VAL — Clock Generator Select Value This bit is effective when the Host Controller supports a programmable clock generator. Values: - 0x0 (FALSE): Host Controller Ver2.0 Compatible Clock Generator - 0x1 (PROG): Programmable Clock Generator
    [9:0] FREQ_SEL_VAL — SDCLK/RCLK Frequency Select Value 10-bit preset value to be set in SDCLK/RCLK Frequency Select field of the Clock Control register described by a Host System.
  0x62 PRESET_DS_R 16-bit ro — Preset Value for Default Speed
    [15:14] DRV_SEL_VAL — Driver Strength Select Value These bits indicate the Driver strength value supported by 1.8V signaling bus speed modes. This field is meaningless for the Default speed mode as it uses 3.3V signaling. Values: - 0x0 (TYPEB): Driver Type B is selected - 0x1 (TYPEA): Driver Type A is selected - 0x2 (TYPEC): Driver Type C is selected - 0x3 (TYPED): Driver Type D is selected
    [10] CLK_GEN_SEL_VAL — Clock Generator Select Value This bit is effective when Host Controller supports programmable clock generator. Values: - 0x0 (FALSE): Host Controller Ver2.0 Compatible Clock Generator - 0x1 (PROG): Programmable Clock Generator
    [9:0] FREQ_SEL_VAL — SDCLK/RCLK Frequency Select Value 10-bit preset value to be set in SDCLK/RCLK Frequency Select field of the Clock Control register described by a Host System.
  0x64 PRESET_HS_R 16-bit ro — Preset Value for High Speed
    [15:14] DRV_SEL_VAL — Driver Strength Select Value These bits indicate the Driver strength value supported by 1.8V signaling bus speed modes. This field is meaningless for High speed mode as it uses 3.3V signaling. Values: - 0x0 (TYPEB): Driver Type B is selected - 0x1 (TYPEA): Driver Type A is selected - 0x2 (TYPEC): Driver Type C is selected - 0x3 (TYPED): Driver Type D is selected
    [10] CLK_GEN_SEL_VAL — Clock Generator Select Value This bit is effective when Host Controller supports programmable clock generator. Values: - 0x0 (FALSE): Host Controller Ver2.0 Compatible Clock Generator - 0x1 (PROG): Programmable Clock Generator
    [9:0] FREQ_SEL_VAL — SDCLK/RCLK Frequency Select Value 10-bit preset value to be set in SDCLK/RCLK Frequency Select field of the Clock Control register described by a Host System.
  0x66 PRESET_SDR12_R 16-bit ro — Preset Value for SDR12
    [15:14] DRV_SEL_VAL — Driver Strength Select Value These bits indicate the Driver strength value supported for the SDR12 bus speed mode. These bits are meaningless for 3.3V signaling. Values: - 0x0 (TYPEB): Driver Type B is selected - 0x1 (TYPEA): Driver Type A is selected - 0x2 (TYPEC): Driver Type C is selected - 0x3 (TYPED): Driver Type D is selected
    [10] CLK_GEN_SEL_VAL — Clock Generator Select Value This bit is effective when Host Controller supports programmable clock generator Values: - 0x0 (FALSE): Host Controller Ver2.0 Compatible Clock Generator - 0x1 (PROG): Programmable Clock Generator
    [9:0] FREQ_SEL_VAL — SDCLK/RCLK Frequency Select Value 10-bit preset value to be set in SDCLK/RCLK Frequency Select field of the Clock Control register described by a Host System.
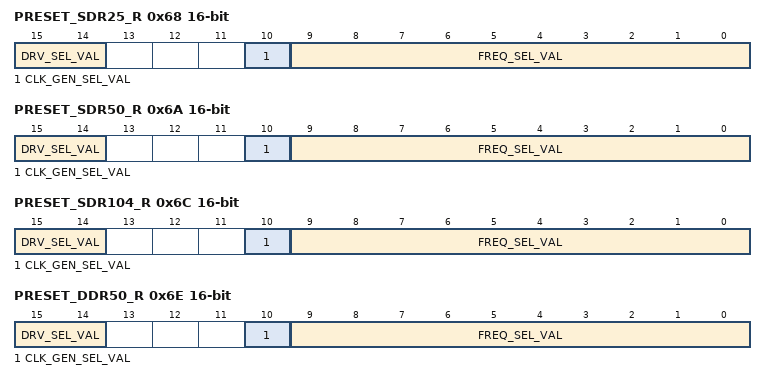
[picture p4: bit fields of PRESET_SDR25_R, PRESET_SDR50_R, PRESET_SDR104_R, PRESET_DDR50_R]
  0x68 PRESET_SDR25_R 16-bit ro — Preset Value for SDR25
    [15:14] DRV_SEL_VAL — Driver Strength Select Value These bits indicate the Driver strength value supported for the SDR12 bus speed mode. These bits are meaningless for 3.3V signaling. Values: - 0x0 (TYPEB): Driver Type B is selected - 0x1 (TYPEA): Driver Type A is selected - 0x2 (TYPEC): Driver Type C is selected - 0x3 (TYPED): Driver Type D is selectedDriver Strength Select Value These bits indicate the Driver strength value supported for the SDR25 bus speed mode. These bits are meaningless for 3.3V signaling. Values: - 0x0 (TYPEB): Driver Type B is selected - 0x1 (TYPEA): Driver Type A is selected - 0x2 (TYPEC): Driver Type C is selected - 0x3 (TYPED): Driver Type D is selected
    [10] CLK_GEN_SEL_VAL — Clock Generator Select Value This bit is effective when Host Controller supports programmable clock generator. Values: - 0x0 (FALSE): Host Controller Ver2.0 Compatible Clock Generator - 0x1 (PROG): Programmable Clock Generator
    [9:0] FREQ_SEL_VAL — SDCLK/RCLK Frequency Select Value 10-bit preset value to be set in SDCLK/RCLK Frequency Select field of the Clock Control register described by a Host System.
  0x6A PRESET_SDR50_R 16-bit ro — Preset Value for SDR50
    [15:14] DRV_SEL_VAL — Driver Strength Select Value These bits indicate Driver strength value supported for SDR50 bus speed mode. These bits are meaningless for 3.3V signaling. Values: - 0x0 (TYPEB): Driver Type B is selected - 0x1 (TYPEA): Driver Type A is selected - 0x2 (TYPEC): Driver Type C is selected - 0x3 (TYPED): Driver Type D is selected
    [10] CLK_GEN_SEL_VAL — Clock Generator Select Value This bit is effective when Host Controller supports programmable clock generator. Values: - 0x0 (FALSE): Host Controller Ver2.0 Compatible Clock Generator - 0x1 (PROG): Programmable Clock Generator
    [9:0] FREQ_SEL_VAL — SDCLK/RCLK Frequency Select Value 10-bit preset value to be set in SDCLK/RCLK Frequency Select field of the Clock Control register described by a Host System.
  0x6C PRESET_SDR104_R 16-bit ro — Preset Value for SDR104
    [15:14] DRV_SEL_VAL — Driver Strength Select Value These bits indicate Driver strength value supported for SDR104 bus speed mode. These bits are meaningless for 3.3V signaling. Values: - 0x0 (TYPEB): Driver Type B is selected - 0x1 (TYPEA): Driver Type A is selected - 0x2 (TYPEC): Driver Type C is selected - 0x3 (TYPED): Driver Type D is selected
    [10] CLK_GEN_SEL_VAL — Clock Generator Select Value This bit is effective when Host Controller supports programmable clock generator. Values: - 0x0 (FALSE): Host Controller Ver2.0 Compatible Clock Generator - 0x1 (PROG): Programmable Clock Generator
    [9:0] FREQ_SEL_VAL — SDCLK/RCLK Frequency Select Value These bits specify a 10-bit preset value that must be set in the SDCLK/RCLK Frequency Select field of the Clock Control register described by a Host System.
  0x6E PRESET_DDR50_R 16-bit ro — Preset Value for DDR50
    [15:14] DRV_SEL_VAL — Driver Strength Select Value These bits indicate Driver strength value supported for DDR50 bus speed mode. These bits are meaningless for 3.3V signaling. Values: - 0x0 (TYPEB): Driver Type B is selected - 0x1 (TYPEA): Driver Type A is selected - 0x2 (TYPEC): Driver Type C is selected - 0x3 (TYPED): Driver Type D is selected
    [10] CLK_GEN_SEL_VAL — Clock Generator Select Value This bit is effective when Host Controller supports programmable clock generator. Values: - 0x0 (FALSE): Host Controller Ver2.0 Compatible Clock Generator - 0x1 (PROG): Programmable Clock Generator
    [9:0] FREQ_SEL_VAL — SDCLK/RCLK Frequency Select Value These bits specify a 10-bit preset value that must be set in the SDCLK/RCLK Frequency Select field of the Clock Control register, as described by a Host System.
